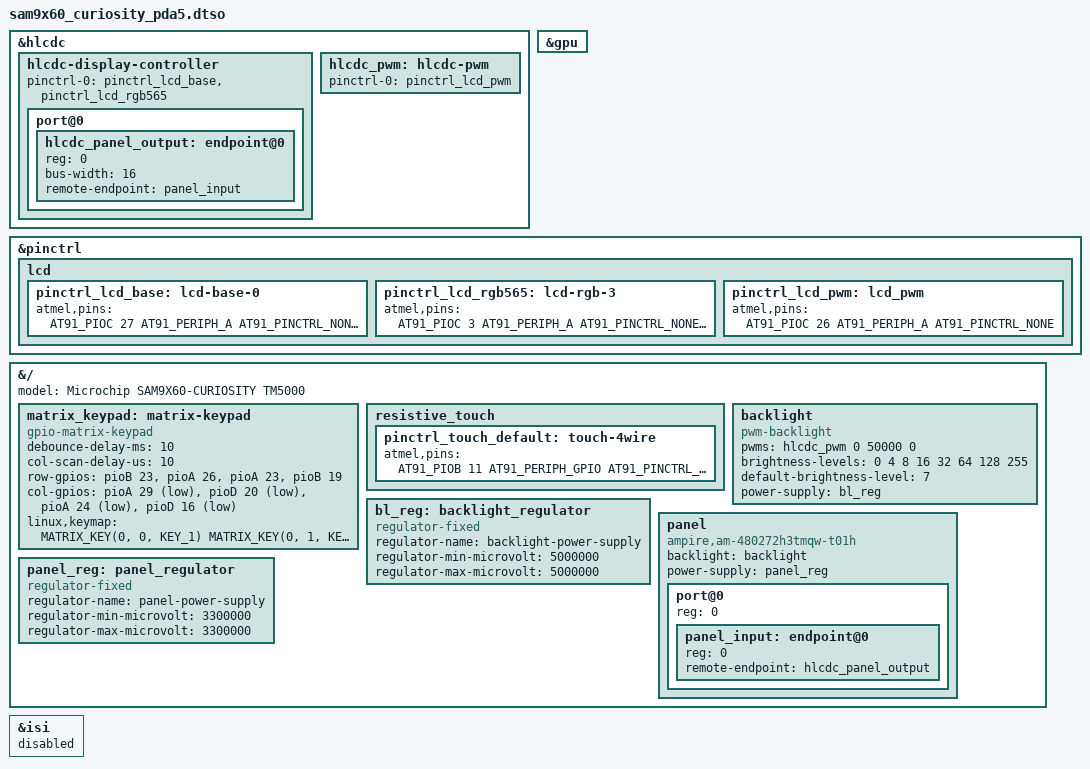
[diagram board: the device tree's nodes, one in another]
// SPDX-License-Identifier: (GPL-2.0+ OR MIT)
/*
 * Device Tree file for SAM9X60-CURIOSITY board
 * overlay blob for PDA5000 LCD.
 *
 * Copyright (C) 2022 Microchip Technology, Inc. and its subsidiaries
 * Author: Durai Manickam KR <durai.manickamkr@microchip.com>
 *
 */
/dts-v1/;
/plugin/;

#include "dt-bindings/pinctrl/at91.h"
#include "dt-bindings/input/input.h"
#include "dt-bindings/gpio/gpio.h"

&hlcdc {
	status = "okay";

	hlcdc-display-controller {
		pinctrl-names = "default";
		pinctrl-0 = <&pinctrl_lcd_base &pinctrl_lcd_rgb565>;
		port@0 {
			#address-cells = <1>;
			#size-cells = <0>;
			hlcdc_panel_output: endpoint@0 {
				reg = <0>;
				bus-width = <16>;
				remote-endpoint = <&panel_input>;
			};
		};
	};

	hlcdc_pwm: hlcdc-pwm {
		pinctrl-names = "default";
		pinctrl-0 = <&pinctrl_lcd_pwm>;
	};
};

&gpu {
	status = "okay";
};

&pinctrl {
	lcd {
		pinctrl_lcd_base: lcd-base-0 {
			atmel,pins = <AT91_PIOC 27 AT91_PERIPH_A AT91_PINCTRL_NONE	/* LCDVSYNC */
				      AT91_PIOC 28 AT91_PERIPH_A AT91_PINCTRL_NONE	/* LCDHSYNC */
				      AT91_PIOC 24 AT91_PERIPH_A AT91_PINCTRL_NONE	/* LCDDISP */
				      AT91_PIOC 29 AT91_PERIPH_A AT91_PINCTRL_NONE	/* LCDDEN */
				      AT91_PIOC 30 AT91_PERIPH_A AT91_PINCTRL_NONE>;	/* LCDPCK */
		};

		pinctrl_lcd_rgb565: lcd-rgb-3 {
			atmel,pins = <AT91_PIOC 3 AT91_PERIPH_A AT91_PINCTRL_NONE	/* LCDD3 pin */
				      AT91_PIOC 4 AT91_PERIPH_A AT91_PINCTRL_NONE	/* LCDD4 pin */
				      AT91_PIOC 5 AT91_PERIPH_A AT91_PINCTRL_NONE	/* LCDD5 pin */
				      AT91_PIOC 6 AT91_PERIPH_A AT91_PINCTRL_NONE	/* LCDD6 pin */
				      AT91_PIOC 7 AT91_PERIPH_A AT91_PINCTRL_NONE	/* LCDD7 pin */
				      AT91_PIOC 10 AT91_PERIPH_A AT91_PINCTRL_NONE	/* LCDD10 pin */
				      AT91_PIOC 11 AT91_PERIPH_A AT91_PINCTRL_NONE	/* LCDD11 pin */
				      AT91_PIOC 12 AT91_PERIPH_A AT91_PINCTRL_NONE	/* LCDD12 pin */
				      AT91_PIOC 13 AT91_PERIPH_A AT91_PINCTRL_NONE	/* LCDD13 pin */
				      AT91_PIOC 14 AT91_PERIPH_A AT91_PINCTRL_NONE	/* LCDD14 pin */
				      AT91_PIOC 15 AT91_PERIPH_A AT91_PINCTRL_NONE	/* LCDD15 pin */
				      AT91_PIOC 19 AT91_PERIPH_A AT91_PINCTRL_NONE	/* LCDD19 pin */
				      AT91_PIOC 20 AT91_PERIPH_A AT91_PINCTRL_NONE	/* LCDD20 pin */
				      AT91_PIOC 21 AT91_PERIPH_A AT91_PINCTRL_NONE	/* LCDD21 pin */
				      AT91_PIOC 22 AT91_PERIPH_A AT91_PINCTRL_NONE	/* LCDD22 pin */
				      AT91_PIOC 23 AT91_PERIPH_A AT91_PINCTRL_NONE>;	/* LCDD23 pin */
		};

		pinctrl_lcd_pwm: lcd_pwm {
			atmel,pins = <AT91_PIOC 26 AT91_PERIPH_A AT91_PINCTRL_NONE>;
		};
	};
};

&{/} {
	model = "Microchip SAM9X60-CURIOSITY TM5000";

	matrix_keypad: matrix-keypad {
		compatible = "gpio-matrix-keypad";
		debounce-delay-ms = <10>;
		col-scan-delay-us = <10>;
		
		row-gpios = <&pioB 23 GPIO_ACTIVE_HIGH
					 &pioA 26 GPIO_ACTIVE_HIGH
					 &pioA 23 GPIO_ACTIVE_HIGH
					 &pioB 19 GPIO_ACTIVE_HIGH>;

		col-gpios = <&pioA 29 GPIO_ACTIVE_LOW
					 &pioD 20 GPIO_ACTIVE_LOW
					 &pioA 24 GPIO_ACTIVE_LOW
					 &pioD 16 GPIO_ACTIVE_LOW>;

		linux,keymap = <MATRIX_KEY(0, 0, KEY_1)
						MATRIX_KEY(0, 1, KEY_2)
						MATRIX_KEY(0, 2, KEY_3)
						MATRIX_KEY(0, 3, KEY_F)
						MATRIX_KEY(1, 0, KEY_4)
						MATRIX_KEY(1, 1, KEY_5)
						MATRIX_KEY(1, 2, KEY_6)
						MATRIX_KEY(1, 3, KEY_UP)
						MATRIX_KEY(2, 0, KEY_7)
						MATRIX_KEY(2, 1, KEY_8)
						MATRIX_KEY(2, 2, KEY_9)
						MATRIX_KEY(2, 3, KEY_DOWN)
						MATRIX_KEY(3, 0, KEY_ESC)
						MATRIX_KEY(3, 1, KEY_0)
						MATRIX_KEY(3, 2, KEY_OK)
						MATRIX_KEY(3, 3, KEY_MENU)>;
	};

	resistive_touch {
		pinctrl_touch_default: touch-4wire {
			atmel,pins =
				<AT91_PIOB 11 AT91_PERIPH_GPIO AT91_PINCTRL_NONE
				 AT91_PIOB 12 AT91_PERIPH_GPIO AT91_PINCTRL_NONE
				 AT91_PIOB 13 AT91_PERIPH_GPIO AT91_PINCTRL_NONE
				 AT91_PIOB 14 AT91_PERIPH_GPIO AT91_PINCTRL_NONE>;
		};
	};

	backlight: backlight {
		compatible = "pwm-backlight";
		pwms = <&hlcdc_pwm 0 50000 0>;
		brightness-levels = <0 4 8 16 32 64 128 255>;
		default-brightness-level = <7>;
		power-supply = <&bl_reg>;
		status = "okay";
	};

	bl_reg: backlight_regulator {
		compatible = "regulator-fixed";
		regulator-name = "backlight-power-supply";
		regulator-min-microvolt = <5000000>;
		regulator-max-microvolt = <5000000>;
		status = "okay";
	};

	panel: panel {
		compatible = "ampire,am-480272h3tmqw-t01h";
		backlight = <&backlight>;
		power-supply = <&panel_reg>;
		#address-cells = <1>;
		#size-cells = <0>;
		status = "okay";

		port@0 {
			reg = <0>;
			#address-cells = <1>;
			#size-cells = <0>;

			panel_input: endpoint@0 {
				reg = <0>;
				remote-endpoint = <&hlcdc_panel_output>;
			};
		};
	};

	panel_reg: panel_regulator {
		compatible = "regulator-fixed";
		regulator-name = "panel-power-supply";
		regulator-min-microvolt = <3300000>;
		regulator-max-microvolt = <3300000>;
		status = "okay";
	};
};

&isi {
	status = "disabled";
};

